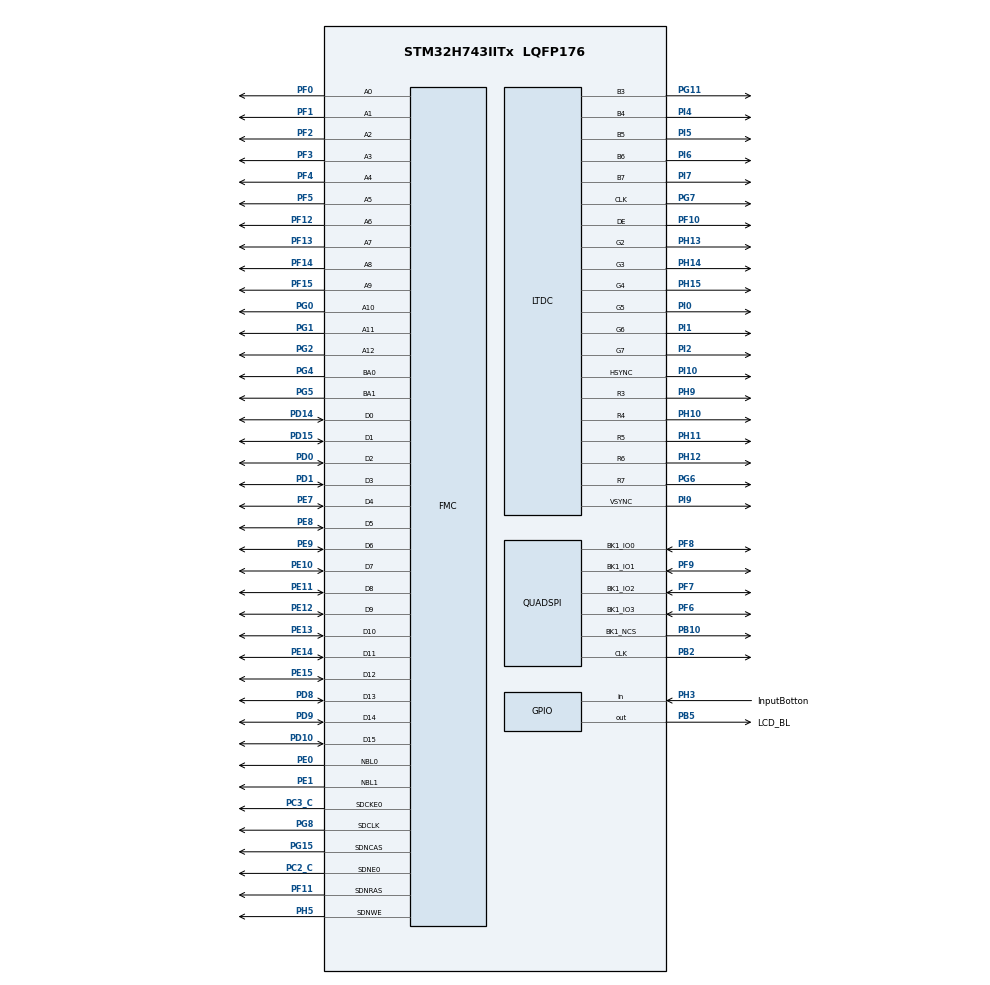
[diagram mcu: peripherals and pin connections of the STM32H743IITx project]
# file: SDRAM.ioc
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CORTEX_M7.CPU_DCache=Enabled
CORTEX_M7.CPU_ICache=Enabled
CORTEX_M7.MPU_Control=__NULL
CORTEX_M7.default_mode_Activation=1
DMA2D.AlphaModeForeground=DMA2D_REPLACE_ALPHA
DMA2D.ColorMode=DMA2D_OUTPUT_RGB565
DMA2D.InputAlphaForeground=255
DMA2D.Mode=DMA2D_M2M
FMC.CASLatency1=FMC_SDRAM_CAS_LATENCY_3
FMC.ColumnBitsNumber1=FMC_SDRAM_COLUMN_BITS_NUM_9
FMC.ExitSelfRefreshDelay1=7
FMC.LoadToActiveDelay1=2
FMC.RCDDelay1=2
FMC.RPDelay1=2
FMC.ReadPipeDelay1=FMC_SDRAM_RPIPE_DELAY_1
FMC.RowCycleDelay1=7
FMC.SDClockPeriod1=FMC_SDRAM_CLOCK_PERIOD_2
FMC.SelfRefreshTime1=4
FMC.WriteRecoveryTime1=3
FREERTOS.Tasks01=defaultTask,24,8910,StartDefaultTask,Default,NULL,Dynamic,NULL,NULL
FREERTOS.configTOTAL_HEAP_SIZE=100000
FREERTOS.configUSE_NEWLIB_REENTRANT=1
LTDC.ActiveH=272
LTDC.ActiveW=480
LTDC.Alpha_L0=255
LTDC.Blue=100
LTDC.FBStartAdress_L0=0xC0000000
LTDC.Green=100
LTDC.HBP=43
LTDC.HFP=8
LTDC.HSync=1
LTDC.ImageHeight_L0=272
LTDC.ImageWidth_L0=480
LTDC.Layers=0
LTDC.PixelFormat_L0=LTDC_PIXEL_FORMAT_RGB565
LTDC.Red=100
LTDC.VBP=12
LTDC.VFP=8
LTDC.VSync=1
LTDC.WindowX1_L0=480
LTDC.WindowY1_L0=272
Mcu.Family=STM32H7
Mcu.Name=STM32H743IITx
Mcu.Package=LQFP176
NVIC.DMA2D_IRQn=true\:5\:0\:false\:false\:true\:true\:true\:true\:true
NVIC.FMC_IRQn=true\:5\:0\:false\:false\:true\:true\:true\:true\:true
NVIC.LTDC_ER_IRQn=true\:5\:0\:false\:false\:true\:true\:true\:true\:true
NVIC.LTDC_IRQn=true\:5\:0\:false\:false\:true\:true\:true\:true\:true
NVIC.PriorityGroup=NVIC_PRIORITYGROUP_4
NVIC.TIM17_IRQn=true\:15\:0\:false\:false\:true\:false\:false\:true\:true
NVIC.TimeBase=TIM17_IRQn
NVIC.TimeBaseIP=TIM17
PB10.Mode=Single Bank 1
PB10.Signal=QUADSPI_BK1_NCS
PB2.Mode=Single Bank 1
PB2.Signal=QUADSPI_CLK
PB5.GPIO_Label=LCD_BL
PB5.Signal=GPIO_Output
PC2_C.GPIO_Mode=GPIO_MODE_AF_PP
PC2_C.GPIO_Speed_High_Default=GPIO_SPEED_FREQ_VERY_HIGH
PC2_C.Mode=SdramChipSelect1_1
PC2_C.Signal=FMC_SDNE0
PC3_C.GPIO_Mode=GPIO_MODE_AF_PP
PC3_C.GPIO_Speed_High_Default=GPIO_SPEED_FREQ_VERY_HIGH
PC3_C.Mode=SdramChipSelect1_1
PC3_C.Signal=FMC_SDCKE0
PD0.GPIO_Mode=GPIO_MODE_AF_PP
PD0.GPIO_Speed_High_Default=GPIO_SPEED_FREQ_VERY_HIGH
PD0.Signal=FMC_D2_DA2
PD1.GPIO_Mode=GPIO_MODE_AF_PP
PD1.GPIO_Speed_High_Default=GPIO_SPEED_FREQ_VERY_HIGH
PD1.Signal=FMC_D3_DA3
PD10.GPIO_Mode=GPIO_MODE_AF_PP
PD10.GPIO_Speed_High_Default=GPIO_SPEED_FREQ_VERY_HIGH
PD10.Signal=FMC_D15_DA15
PD14.GPIO_Mode=GPIO_MODE_AF_PP
PD14.GPIO_Speed_High_Default=GPIO_SPEED_FREQ_VERY_HIGH
PD14.Signal=FMC_D0_DA0
PD15.GPIO_Mode=GPIO_MODE_AF_PP
PD15.GPIO_Speed_High_Default=GPIO_SPEED_FREQ_VERY_HIGH
PD15.Signal=FMC_D1_DA1
PD8.GPIO_Mode=GPIO_MODE_AF_PP
PD8.GPIO_Speed_High_Default=GPIO_SPEED_FREQ_VERY_HIGH
PD8.Signal=FMC_D13_DA13
PD9.GPIO_Mode=GPIO_MODE_AF_PP
PD9.GPIO_Speed_High_Default=GPIO_SPEED_FREQ_VERY_HIGH
PD9.Signal=FMC_D14_DA14
PE0.GPIO_Mode=GPIO_MODE_AF_PP
PE0.GPIO_Speed_High_Default=GPIO_SPEED_FREQ_VERY_HIGH
PE0.Signal=FMC_NBL0
PE1.GPIO_Mode=GPIO_MODE_AF_PP
PE1.GPIO_Speed_High_Default=GPIO_SPEED_FREQ_VERY_HIGH
PE1.Signal=FMC_NBL1
PE10.GPIO_Mode=GPIO_MODE_AF_PP
PE10.GPIO_Speed_High_Default=GPIO_SPEED_FREQ_VERY_HIGH
PE10.Signal=FMC_D7_DA7
PE11.GPIO_Mode=GPIO_MODE_AF_PP
PE11.GPIO_Speed_High_Default=GPIO_SPEED_FREQ_VERY_HIGH
PE11.Signal=FMC_D8_DA8
PE12.GPIO_Mode=GPIO_MODE_AF_PP
PE12.GPIO_Speed_High_Default=GPIO_SPEED_FREQ_VERY_HIGH
PE12.Signal=FMC_D9_DA9
PE13.GPIO_Mode=GPIO_MODE_AF_PP
PE13.GPIO_Speed_High_Default=GPIO_SPEED_FREQ_VERY_HIGH
PE13.Signal=FMC_D10_DA10
PE14.GPIO_Mode=GPIO_MODE_AF_PP
PE14.GPIO_Speed_High_Default=GPIO_SPEED_FREQ_VERY_HIGH
PE14.Signal=FMC_D11_DA11
PE15.GPIO_Mode=GPIO_MODE_AF_PP
PE15.GPIO_Speed_High_Default=GPIO_SPEED_FREQ_VERY_HIGH
PE15.Signal=FMC_D12_DA12
PE7.GPIO_Mode=GPIO_MODE_AF_PP
PE7.GPIO_Speed_High_Default=GPIO_SPEED_FREQ_VERY_HIGH
PE7.Signal=FMC_D4_DA4
PE8.GPIO_Mode=GPIO_MODE_AF_PP
PE8.GPIO_Speed_High_Default=GPIO_SPEED_FREQ_VERY_HIGH
PE8.Signal=FMC_D5_DA5
PE9.GPIO_Mode=GPIO_MODE_AF_PP
PE9.GPIO_Speed_High_Default=GPIO_SPEED_FREQ_VERY_HIGH
PE9.Signal=FMC_D6_DA6
PF0.GPIO_Mode=GPIO_MODE_AF_PP
PF0.GPIO_Speed_High_Default=GPIO_SPEED_FREQ_VERY_HIGH
PF0.Signal=FMC_A0
PF1.GPIO_Mode=GPIO_MODE_AF_PP
PF1.GPIO_Speed_High_Default=GPIO_SPEED_FREQ_VERY_HIGH
PF1.Signal=FMC_A1
PF10.Mode=RGB565
PF10.Signal=LTDC_DE
PF11.GPIO_Mode=GPIO_MODE_AF_PP
PF11.GPIO_Speed_High_Default=GPIO_SPEED_FREQ_VERY_HIGH
PF11.Signal=FMC_SDNRAS
PF12.GPIO_Mode=GPIO_MODE_AF_PP
PF12.GPIO_Speed_High_Default=GPIO_SPEED_FREQ_VERY_HIGH
PF12.Signal=FMC_A6
PF13.GPIO_Mode=GPIO_MODE_AF_PP
PF13.GPIO_Speed_High_Default=GPIO_SPEED_FREQ_VERY_HIGH
PF13.Signal=FMC_A7
PF14.GPIO_Mode=GPIO_MODE_AF_PP
PF14.GPIO_Speed_High_Default=GPIO_SPEED_FREQ_VERY_HIGH
PF14.Signal=FMC_A8
PF15.GPIO_Mode=GPIO_MODE_AF_PP
PF15.GPIO_Speed_High_Default=GPIO_SPEED_FREQ_VERY_HIGH
PF15.Signal=FMC_A9
PF2.GPIO_Mode=GPIO_MODE_AF_PP
PF2.GPIO_Speed_High_Default=GPIO_SPEED_FREQ_VERY_HIGH
PF2.Signal=FMC_A2
PF3.GPIO_Mode=GPIO_MODE_AF_PP
PF3.GPIO_Speed_High_Default=GPIO_SPEED_FREQ_VERY_HIGH
PF3.Signal=FMC_A3
PF4.GPIO_Mode=GPIO_MODE_AF_PP
PF4.GPIO_Speed_High_Default=GPIO_SPEED_FREQ_VERY_HIGH
PF4.Signal=FMC_A4
PF5.GPIO_Mode=GPIO_MODE_AF_PP
PF5.GPIO_Speed_High_Default=GPIO_SPEED_FREQ_VERY_HIGH
PF5.Signal=FMC_A5
PF6.Mode=Single Bank 1
PF6.Signal=QUADSPI_BK1_IO3
PF7.Mode=Single Bank 1
PF7.Signal=QUADSPI_BK1_IO2
PF8.Mode=Single Bank 1
PF8.Signal=QUADSPI_BK1_IO0
PF9.Mode=Single Bank 1
PF9.Signal=QUADSPI_BK1_IO1
PG0.GPIO_Mode=GPIO_MODE_AF_PP
PG0.GPIO_Speed_High_Default=GPIO_SPEED_FREQ_VERY_HIGH
PG0.Signal=FMC_A10
PG1.GPIO_Mode=GPIO_MODE_AF_PP
PG1.GPIO_Speed_High_Default=GPIO_SPEED_FREQ_VERY_HIGH
PG1.Signal=FMC_A11
PG11.Mode=RGB565
PG11.Signal=LTDC_B3
PG15.GPIO_Mode=GPIO_MODE_AF_PP
PG15.GPIO_Speed_High_Default=GPIO_SPEED_FREQ_VERY_HIGH
PG15.Signal=FMC_SDNCAS
PG2.GPIO_Mode=GPIO_MODE_AF_PP
PG2.GPIO_Speed_High_Default=GPIO_SPEED_FREQ_VERY_HIGH
PG2.Signal=FMC_A12
PG4.GPIO_Mode=GPIO_MODE_AF_PP
PG4.GPIO_Speed_High_Default=GPIO_SPEED_FREQ_VERY_HIGH
PG4.Signal=FMC_A14_BA0
PG5.GPIO_Mode=GPIO_MODE_AF_PP
PG5.GPIO_Speed_High_Default=GPIO_SPEED_FREQ_VERY_HIGH
PG5.Signal=FMC_A15_BA1
PG6.Mode=RGB565
PG6.Signal=LTDC_R7
PG7.Mode=RGB565
PG7.Signal=LTDC_CLK
PG8.GPIO_Mode=GPIO_MODE_AF_PP
PG8.GPIO_Speed_High_Default=GPIO_SPEED_FREQ_VERY_HIGH
PG8.Signal=FMC_SDCLK
PH0-OSC_IN\ (PH0).Mode=HSE-External-Oscillator
PH0-OSC_IN\ (PH0).Signal=RCC_OSC_IN
PH1-OSC_OUT\ (PH1).Mode=HSE-External-Oscillator
PH1-OSC_OUT\ (PH1).Signal=RCC_OSC_OUT
PH10.Mode=RGB565
PH10.Signal=LTDC_R4
PH11.Mode=RGB565
PH11.Signal=LTDC_R5
PH12.Mode=RGB565
PH12.Signal=LTDC_R6
PH13.Mode=RGB565
PH13.Signal=LTDC_G2
PH14.Mode=RGB565
PH14.Signal=LTDC_G3
PH15.Mode=RGB565
PH15.Signal=LTDC_G4
PH3.GPIO_Label=InputBotton
PH3.Signal=GPIO_Input
PH5.Signal=FMC_SDNWE
PH9.Mode=RGB565
PH9.Signal=LTDC_R3
PI0.Mode=RGB565
PI0.Signal=LTDC_G5
PI1.Mode=RGB565
PI1.Signal=LTDC_G6
PI10.Mode=RGB565
PI10.Signal=LTDC_HSYNC
PI2.Mode=RGB565
PI2.Signal=LTDC_G7
PI4.Mode=RGB565
PI4.Signal=LTDC_B4
PI5.Mode=RGB565
PI5.Signal=LTDC_B5
PI6.Mode=RGB565
PI6.Signal=LTDC_B6
PI7.Mode=RGB565
PI7.Signal=LTDC_B7
PI9.Mode=RGB565
PI9.Signal=LTDC_VSYNC
ProjectManager.HeapSize=0x200
ProjectManager.StackSize=0x400
ProjectManager.TargetToolchain=STM32CubeIDE
RCC.ADCFreq_Value=50390625
RCC.APB1Freq_Value=120000000
RCC.APB2Freq_Value=120000000
RCC.APB3Freq_Value=120000000
RCC.APB4Freq_Value=120000000
RCC.CortexFreq_Value=480000000
RCC.D1PPRE=RCC_APB3_DIV2
RCC.D2PPRE1=RCC_APB1_DIV2
RCC.D2PPRE2=RCC_APB2_DIV2
RCC.D3PPRE=RCC_APB4_DIV2
RCC.DIVM1=5
RCC.DIVM3=25
RCC.DIVN1=192
RCC.DIVN3=200
RCC.DIVR3=10
RCC.FMCCLockSelection=RCC_FMCCLKSOURCE_CLKP
RCC.HCLKFreq_Value=240000000
RCC.HPRE=RCC_HCLK_DIV2
RCC.PLLFRACN=0
RCC.PLLSourceVirtual=RCC_PLLSOURCE_HSE
RCC.SYSCLKFreq_VALUE=480000000
RCC.SYSCLKSource=RCC_SYSCLKSOURCE_PLLCLK
RCC.USBFreq_Value=480000000
SH.FMC_A0.0=FMC_A0,13b-sda1
SH.FMC_A1.0=FMC_A1,13b-sda1
SH.FMC_A10.0=FMC_A10,13b-sda1
SH.FMC_A11.0=FMC_A11,13b-sda1
SH.FMC_A12.0=FMC_A12,13b-sda1
SH.FMC_A14_BA0.0=FMC_BA0,FourSdramBanks1
SH.FMC_A15_BA1.0=FMC_BA1,FourSdramBanks1
SH.FMC_A2.0=FMC_A2,13b-sda1
SH.FMC_A3.0=FMC_A3,13b-sda1
SH.FMC_A4.0=FMC_A4,13b-sda1
SH.FMC_A5.0=FMC_A5,13b-sda1
SH.FMC_A6.0=FMC_A6,13b-sda1
SH.FMC_A7.0=FMC_A7,13b-sda1
SH.FMC_A8.0=FMC_A8,13b-sda1
SH.FMC_A9.0=FMC_A9,13b-sda1
SH.FMC_D0_DA0.0=FMC_D0,sd-16b-d1
SH.FMC_D10_DA10.0=FMC_D10,sd-16b-d1
SH.FMC_D11_DA11.0=FMC_D11,sd-16b-d1
SH.FMC_D12_DA12.0=FMC_D12,sd-16b-d1
SH.FMC_D13_DA13.0=FMC_D13,sd-16b-d1
SH.FMC_D14_DA14.0=FMC_D14,sd-16b-d1
SH.FMC_D15_DA15.0=FMC_D15,sd-16b-d1
SH.FMC_D1_DA1.0=FMC_D1,sd-16b-d1
SH.FMC_D2_DA2.0=FMC_D2,sd-16b-d1
SH.FMC_D3_DA3.0=FMC_D3,sd-16b-d1
SH.FMC_D4_DA4.0=FMC_D4,sd-16b-d1
SH.FMC_D5_DA5.0=FMC_D5,sd-16b-d1
SH.FMC_D6_DA6.0=FMC_D6,sd-16b-d1
SH.FMC_D7_DA7.0=FMC_D7,sd-16b-d1
SH.FMC_D8_DA8.0=FMC_D8,sd-16b-d1
SH.FMC_D9_DA9.0=FMC_D9,sd-16b-d1
SH.FMC_NBL0.0=FMC_NBL0,Sd2ByteEnable1
SH.FMC_NBL1.0=FMC_NBL1,Sd2ByteEnable1
SH.FMC_SDCLK.0=FMC_SDCLK,13b-sda1
SH.FMC_SDNCAS.0=FMC_SDNCAS,13b-sda1
SH.FMC_SDNRAS.0=FMC_SDNRAS,13b-sda1
SH.FMC_SDNWE.0=FMC_SDNWE,13b-sda1
STMicroelectronics.X-CUBE-TOUCHGFX.4.26.0.ApplicationCcGraphicsJjApplication=TouchGFXOoGenerator
STMicroelectronics.X-CUBE-TOUCHGFX.4.26.0.tgfx_address1=0xC0000000
STMicroelectronics.X-CUBE-TOUCHGFX.4.26.0.tgfx_address2=0xC4000000
STMicroelectronics.X-CUBE-TOUCHGFX.4.26.0.tgfx_buffering_strategy=Single
STMicroelectronics.X-CUBE-TOUCHGFX.4.26.0.tgfx_display_interface=disp_ltdc
STMicroelectronics.X-CUBE-TOUCHGFX.4.26.0.tgfx_framebuffer_stride=Enabled
STMicroelectronics.X-CUBE-TOUCHGFX.4.26.0.tgfx_hardware_accelerator=dma_2d
STMicroelectronics.X-CUBE-TOUCHGFX.4.26.0.tgfx_location=By Address
STMicroelectronics.X-CUBE-TOUCHGFX.4.26.0.tgfx_oswrapper=CMSIS V2
STMicroelectronics.X-CUBE-TOUCHGFX.4.26.0.tgfx_vsync=vsync_ltdc
STMicroelectronics.X-CUBE-TOUCHGFX.4.26.0_IsPackSelfContextualization=true
VP_CRC_VS_CRC.Mode=CRC_Activate
VP_DMA2D_VS_DMA2D.Mode=DMA2D_Activate
VP_FREERTOS_VS_CMSIS_V2.Mode=CMSIS_V2
VP_MEMORYMAP_VS_MEMORYMAP.Mode=CurAppReg
VP_STMicroelectronics.X-CUBE-TOUCHGFX_VS_GraphicsJjApplication_4.26.0.Mode=GraphicsJjApplication
VP_SYS_VS_tim17.Mode=TIM17
board=custom

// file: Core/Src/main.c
/* USER CODE BEGIN Header */
/**
  ******************************************************************************
  * @file           : main.c
  * @brief          : Main program body
  ******************************************************************************
  * @attention
  *
  * Copyright (c) 2025 STMicroelectronics.
  * All rights reserved.
  *
  * This software is licensed under terms that can be found in the LICENSE file
  * in the root directory of this software component.
  * If no LICENSE file comes with this software, it is provided AS-IS.
  *
  ******************************************************************************
  */
/* USER CODE END Header */
#include "main.h"
#include "cmsis_os.h"
#include "app_touchgfx.h"

/* USER CODE BEGIN Includes */
#include "imag.h"
/* USER CODE END Includes */

/* USER CODE BEGIN PTD */
#define SDRAM_BANK_ADDR ((uint32_t)0xC0000000) // Bank 1 base address
#define TEST_SIZE 256 // Test 256 16-bit words (512 bytes)
/* USER CODE END PTD */

/* USER CODE BEGIN PD */
#define SDRAM_Size 32*1024*1024 //32M bytes
#define SDRAM_BANK_ADDR ((uint32_t)0xC0000000) // FMC SDRAM data base address
#define FMC_COMMAND_TARGET_BANK FMC_SDRAM_CMD_TARGET_BANK1 // SDRAM bank selection
#define SDRAM_TIMEOUT ((uint32_t)0x1000) // Timeout judgment time

#define SDRAM_MODEREG_BURST_LENGTH_1             ((uint16_t)0x0000)
#define SDRAM_MODEREG_BURST_LENGTH_2             ((uint16_t)0x0001)
#define SDRAM_MODEREG_BURST_LENGTH_4             ((uint16_t)0x0002)
#define SDRAM_MODEREG_BURST_LENGTH_8             ((uint16_t)0x0004)
#define SDRAM_MODEREG_BURST_TYPE_SEQUENTIAL      ((uint16_t)0x0000)
#define SDRAM_MODEREG_BURST_TYPE_INTERLEAVED     ((uint16_t)0x0008)
#define SDRAM_MODEREG_CAS_LATENCY_2              ((uint16_t)0x0020)
#define SDRAM_MODEREG_CAS_LATENCY_3              ((uint16_t)0x0030)
#define SDRAM_MODEREG_OPERATING_MODE_STANDARD    ((uint16_t)0x0000)
#define SDRAM_MODEREG_WRITEBURST_MODE_PROGRAMMED ((uint16_t)0x0000)
#define SDRAM_MODEREG_WRITEBURST_MODE_SINGLE     ((uint16_t)0x0200)

FMC_SDRAM_CommandTypeDef command; //Control command

/* USER CODE END PD */

/* USER CODE BEGIN PM */
#define LCD_WIDTH  480
#define LCD_HEIGHT 272
#define FRAMEBUFFER_ADDR 0xC0000000 // SDRAM base address

#define COLOR_RED   0xF800
#define COLOR_GREEN 0x07E0
#define COLOR_BLUE  0x001F
#define COLOR_BLACK 0x0000
#define COLOR_WHITE 0xFFFF
/* USER CODE END PM */

CRC_HandleTypeDef hcrc;

DMA2D_HandleTypeDef hdma2d;

LTDC_HandleTypeDef hltdc;

QSPI_HandleTypeDef hqspi;

SDRAM_HandleTypeDef hsdram1;

/* Definitions for defaultTask */
osThreadId_t defaultTaskHandle;
const osThreadAttr_t defaultTask_attributes = {
  .name = "defaultTask",
  .stack_size = 8910 * 4,
  .priority = (osPriority_t) osPriorityNormal,
};

void SystemClock_Config(void);
void PeriphCommonClock_Config(void);
static void MX_GPIO_Init(void);
static void MX_FMC_Init(void);
static void MX_LTDC_Init(void);
static void MX_DMA2D_Init(void);
static void MX_CRC_Init(void);
static void MX_QUADSPI_Init(void);
void StartDefaultTask(void *argument);

/* USER CODE BEGIN PFP */
void MPU_Config(void);
void FillFramebuffer(uint32_t framebuffer_addr, uint16_t color, uint16_t width, uint16_t height);

uint16_t *fb_ptr = (uint16_t *)FRAMEBUFFER_ADDR;
/* USER CODE END PFP */

/* USER CODE BEGIN 0 */
uint32_t GeneralCounter =0 ;

void SDRAM_Initialization_Sequence(SDRAM_HandleTypeDef *hsdram, FMC_SDRAM_CommandTypeDef *Command)
{
	__IO uint32_t tmpmrd = 0;

	/* Configure a clock configuration enable command */
	Command->CommandMode = FMC_SDRAM_CMD_CLK_ENABLE; // Turn on the SDRAM clock
	Command->CommandTarget = FMC_COMMAND_TARGET_BANK; //Select the area to be controlled
	Command->AutoRefreshNumber 		= 1;
	Command->ModeRegisterDefinition 	= 0;

	HAL_SDRAM_SendCommand(hsdram, Command, SDRAM_TIMEOUT); // Send control command
	HAL_Delay(1); // Delay wait

	/* Configure a PALL (precharge all) command */
	Command->CommandMode = FMC_SDRAM_CMD_PALL; // Precharge command
	Command->CommandTarget = FMC_COMMAND_TARGET_BANK; //Select the area to be controlled
	Command->AutoRefreshNumber 		= 1;
	Command->ModeRegisterDefinition 	= 0;

	HAL_SDRAM_SendCommand(hsdram, Command, SDRAM_TIMEOUT); // Send control command

	/* Configure a Auto-Refresh command */
	Command->CommandMode = FMC_SDRAM_CMD_AUTOREFRESH_MODE; // Use automatic refresh
	Command->CommandTarget = FMC_COMMAND_TARGET_BANK; //Select the area to be controlled
	Command->AutoRefreshNumber = 8; //Number of automatic refreshes
	Command->ModeRegisterDefinition 	= 0;

	HAL_SDRAM_SendCommand(hsdram, Command, SDRAM_TIMEOUT); // Send control command

	/* Program the external memory mode register */
	tmpmrd = (uint32_t)SDRAM_MODEREG_BURST_LENGTH_2         |
							SDRAM_MODEREG_BURST_TYPE_SEQUENTIAL   |
							SDRAM_MODEREG_CAS_LATENCY_3           |
							SDRAM_MODEREG_OPERATING_MODE_STANDARD |
							SDRAM_MODEREG_WRITEBURST_MODE_SINGLE;

	Command->CommandMode = FMC_SDRAM_CMD_LOAD_MODE; // Load mode register command
	Command->CommandTarget = FMC_COMMAND_TARGET_BANK; //Select the area to be controlled
	Command->AutoRefreshNumber 		= 1;
	Command->ModeRegisterDefinition 	= tmpmrd;

	HAL_SDRAM_SendCommand(hsdram, Command, SDRAM_TIMEOUT); // Send control command

	HAL_SDRAM_ProgramRefreshRate(hsdram, 918); // Configure refresh rate

}

uint16_t  *DataTOLCD = (uint16_t*)FRAMEBUFFER_ADDR ;
/* USER CODE END 0 */

int main(void)
{

  /* USER CODE BEGIN 1 */
  MPU_Config();
  /* USER CODE END 1 */

  /* Enable the CPU Cache */

  /* Enable I-Cache---------------------------------------------------------*/
  SCB_EnableICache();

  /* Enable D-Cache---------------------------------------------------------*/
  SCB_EnableDCache();

  /* MCU Configuration--------------------------------------------------------*/

  /* Reset of all peripherals, Initializes the Flash interface and the Systick. */
  HAL_Init();

  /* Configure the system clock */
  SystemClock_Config();

  /* Configure the peripherals common clocks */
  PeriphCommonClock_Config();

  /* USER CODE BEGIN SysInit */
//  MPU_Config();
  /* USER CODE END SysInit */

  /* Initialize all configured peripherals */
  MX_GPIO_Init();
  MX_FMC_Init();
  MX_LTDC_Init();
  MX_DMA2D_Init();
  MX_CRC_Init();
  MX_QUADSPI_Init();
  MX_TouchGFX_Init();
  /* Call PreOsInit function */
  MX_TouchGFX_PreOSInit();
  /* USER CODE BEGIN 2 */
  HAL_GPIO_WritePin(LCD_BL_GPIO_Port, LCD_BL_Pin, 1);

//	uint16_t write_pattern = 0xA5A5; // Test patterns
//	uint16_t read_data;
//	uint32_t i;
//	uint8_t errors = 0;

//      // Write pattern to SDRAM
//      for (i = 0; i < TEST_SIZE; i++) {
//          *(__IO uint32_t*)(SDRAM_BANK_ADDR + 4*i) = (uint32_t)0x00;
//      }
//
//      for (i = 0; i < TEST_SIZE; i++) {
//          *(__IO uint32_t*)(SDRAM_BANK_ADDR + 4*i) = (uint32_t)0x19;
//      }
//
//      // Read back and verify
//      for (i = 0; i < TEST_SIZE; i++) {
//          read_data = *(__IO uint16_t*)(SDRAM_BANK_ADDR + (i * 2));
//          if (read_data != write_pattern) {
//              errors++; // Track errors
//          }
//      }

      LTDC_LayerCfgTypeDef layer_cfg = {0};
      layer_cfg.WindowX0 = 0;
      layer_cfg.WindowX1 = LCD_WIDTH;
      layer_cfg.WindowY0 = 0;
      layer_cfg.WindowY1 = LCD_HEIGHT;
      layer_cfg.PixelFormat = LTDC_PIXEL_FORMAT_RGB565;
      layer_cfg.FBStartAdress = FRAMEBUFFER_ADDR; // SDRAM base
      layer_cfg.Alpha = 255; // Opaque
      layer_cfg.Alpha0 = 0;
      layer_cfg.BlendingFactor1 = LTDC_BLENDING_FACTOR1_PAxCA;
      layer_cfg.BlendingFactor2 = LTDC_BLENDING_FACTOR2_PAxCA;
      layer_cfg.ImageWidth = LCD_WIDTH;
      layer_cfg.ImageHeight = LCD_HEIGHT;

      HAL_LTDC_ConfigLayer(&hltdc, &layer_cfg, 0); // Layer 0
      HAL_LTDC_EnableColorKeying(&hltdc, 0); // Optional, disable color keying
      HAL_LTDC_SetAddress(&hltdc, FRAMEBUFFER_ADDR, 0); // Set framebuffer address
  /* USER CODE END 2 */

  /* Init scheduler */
  osKernelInitialize();

  /* Create the thread(s) */
  /* creation of defaultTask */
  defaultTaskHandle = osThreadNew(StartDefaultTask, NULL, &defaultTask_attributes);

  /* Start scheduler */
  osKernelStart();

  /* We should never get here as control is now taken by the scheduler */

  /* Infinite loop */
  /* USER CODE BEGIN WHILE */
  while (1)
  {
//
//		FillFramebuffer(FRAMEBUFFER_ADDR, COLOR_RED, LCD_WIDTH, LCD_HEIGHT);
//		HAL_Delay(500); // Wait 2 seconds
//
//		// Fill with green
//		FillFramebuffer(FRAMEBUFFER_ADDR, COLOR_GREEN, LCD_WIDTH, LCD_HEIGHT);
//		HAL_Delay(500);
//
//		// Fill with blue
//		FillFramebuffer(FRAMEBUFFER_ADDR, COLOR_BLUE, LCD_WIDTH, LCD_HEIGHT);
//		HAL_Delay(500);
//
//		// Fill with white
//		FillFramebuffer(FRAMEBUFFER_ADDR, COLOR_WHITE, LCD_WIDTH, LCD_HEIGHT);
//		HAL_Delay(500);
//
//		// Fill with black
//		FillFramebuffer(FRAMEBUFFER_ADDR, COLOR_BLACK, LCD_WIDTH, LCD_HEIGHT);
//		HAL_Delay(500);
//
//	    for(int i =0 ;i  < sizeof(gImage_TestImage) / 2  ;i++){
//	    	fb_ptr[i] = gImage_TestImage[i] | gImage_TestImage[i+1];
//	    }

//     for(int i =0  ; i< sizeof(IMG_20250926_153935 ) ;i++){
//    	 DataTOLCD[i] = IMG_20250926_153935[i];
//    	 i++;
//     }
//	  HAL_DMA2D_Start(&hdma2d, (uint32_t)IMG_20250926_153935, FRAMEBUFFER_ADDR, 480, 272);
//	  HAL_DMA2D_PollForTransfer(&hdma2d, 100);
//
//	  HAL_Delay(500);
//
//	  HAL_DMA2D_Start(&hdma2d, (uint32_t)AliImage1, FRAMEBUFFER_ADDR, 480, 272);
//	  HAL_DMA2D_PollForTransfer(&hdma2d, 100);
//	  HAL_Delay(500);

	  HAL_DMA2D_Start(&hdma2d, (uint32_t)AlireImage2, FRAMEBUFFER_ADDR, 480, 272);
	  HAL_DMA2D_PollForTransfer(&hdma2d, 100);

	  HAL_Delay(500);
//     HAL_Delay(500) ;
//
//
//     for(int i =0  ; i< 272 * 480 ;i++){
//    	 DataTOLCD[i] = COLOR_GREEN;
//     }
//
//     HAL_Delay(500) ;

	  GeneralCounter ++ ;
    /* USER CODE END WHILE */

  }
}

void SystemClock_Config(void)
{
  RCC_OscInitTypeDef RCC_OscInitStruct = {0};
  RCC_ClkInitTypeDef RCC_ClkInitStruct = {0};

  /** Supply configuration update enable
  */
  HAL_PWREx_ConfigSupply(PWR_LDO_SUPPLY);

  /** Configure the main internal regulator output voltage
  */
  __HAL_PWR_VOLTAGESCALING_CONFIG(PWR_REGULATOR_VOLTAGE_SCALE0);

  while(!__HAL_PWR_GET_FLAG(PWR_FLAG_VOSRDY)) {}

  /** Initializes the RCC Oscillators according to the specified parameters
  * in the RCC_OscInitTypeDef structure.
  */
  RCC_OscInitStruct.OscillatorType = RCC_OSCILLATORTYPE_HSI|RCC_OSCILLATORTYPE_HSE;
  RCC_OscInitStruct.HSEState = RCC_HSE_ON;
  RCC_OscInitStruct.HSIState = RCC_HSI_DIV1;
  RCC_OscInitStruct.HSICalibrationValue = RCC_HSICALIBRATION_DEFAULT;
  RCC_OscInitStruct.PLL.PLLState = RCC_PLL_ON;
  RCC_OscInitStruct.PLL.PLLSource = RCC_PLLSOURCE_HSE;
  RCC_OscInitStruct.PLL.PLLM = 5;
  RCC_OscInitStruct.PLL.PLLN = 192;
  RCC_OscInitStruct.PLL.PLLP = 2;
  RCC_OscInitStruct.PLL.PLLQ = 2;
  RCC_OscInitStruct.PLL.PLLR = 2;
  RCC_OscInitStruct.PLL.PLLRGE = RCC_PLL1VCIRANGE_2;
  RCC_OscInitStruct.PLL.PLLVCOSEL = RCC_PLL1VCOWIDE;
  RCC_OscInitStruct.PLL.PLLFRACN = 0;
  if (HAL_RCC_OscConfig(&RCC_OscInitStruct) != HAL_OK)
  {
    Error_Handler();
  }

  /** Initializes the CPU, AHB and APB buses clocks
  */
  RCC_ClkInitStruct.ClockType = RCC_CLOCKTYPE_HCLK|RCC_CLOCKTYPE_SYSCLK
                              |RCC_CLOCKTYPE_PCLK1|RCC_CLOCKTYPE_PCLK2
                              |RCC_CLOCKTYPE_D3PCLK1|RCC_CLOCKTYPE_D1PCLK1;
  RCC_ClkInitStruct.SYSCLKSource = RCC_SYSCLKSOURCE_PLLCLK;
  RCC_ClkInitStruct.SYSCLKDivider = RCC_SYSCLK_DIV1;
  RCC_ClkInitStruct.AHBCLKDivider = RCC_HCLK_DIV2;
  RCC_ClkInitStruct.APB3CLKDivider = RCC_APB3_DIV2;
  RCC_ClkInitStruct.APB1CLKDivider = RCC_APB1_DIV2;
  RCC_ClkInitStruct.APB2CLKDivider = RCC_APB2_DIV2;
  RCC_ClkInitStruct.APB4CLKDivider = RCC_APB4_DIV2;

  if (HAL_RCC_ClockConfig(&RCC_ClkInitStruct, FLASH_LATENCY_4) != HAL_OK)
  {
    Error_Handler();
  }
}

void PeriphCommonClock_Config(void)
{
  RCC_PeriphCLKInitTypeDef PeriphClkInitStruct = {0};

  /** Initializes the peripherals clock
  */
  PeriphClkInitStruct.PeriphClockSelection = RCC_PERIPHCLK_CKPER;
  PeriphClkInitStruct.CkperClockSelection = RCC_CLKPSOURCE_HSI;
  if (HAL_RCCEx_PeriphCLKConfig(&PeriphClkInitStruct) != HAL_OK)
  {
    Error_Handler();
  }
}

static void MX_CRC_Init(void)
{

  hcrc.Instance = CRC;
  hcrc.Init.DefaultPolynomialUse = DEFAULT_POLYNOMIAL_ENABLE;
  hcrc.Init.DefaultInitValueUse = DEFAULT_INIT_VALUE_ENABLE;
  hcrc.Init.InputDataInversionMode = CRC_INPUTDATA_INVERSION_NONE;
  hcrc.Init.OutputDataInversionMode = CRC_OUTPUTDATA_INVERSION_DISABLE;
  hcrc.InputDataFormat = CRC_INPUTDATA_FORMAT_BYTES;
  if (HAL_CRC_Init(&hcrc) != HAL_OK)
  {
    Error_Handler();
  }

}

static void MX_DMA2D_Init(void)
{

  hdma2d.Instance = DMA2D;
  hdma2d.Init.Mode = DMA2D_M2M;
  hdma2d.Init.ColorMode = DMA2D_OUTPUT_RGB565;
  hdma2d.Init.OutputOffset = 0;
  hdma2d.LayerCfg[1].InputOffset = 0;
  hdma2d.LayerCfg[1].InputColorMode = DMA2D_INPUT_RGB565;
  hdma2d.LayerCfg[1].AlphaMode = DMA2D_REPLACE_ALPHA;
  hdma2d.LayerCfg[1].InputAlpha = 255;
  hdma2d.LayerCfg[1].AlphaInverted = DMA2D_REGULAR_ALPHA;
  hdma2d.LayerCfg[1].RedBlueSwap = DMA2D_RB_REGULAR;
  hdma2d.LayerCfg[1].ChromaSubSampling = DMA2D_NO_CSS;
  if (HAL_DMA2D_Init(&hdma2d) != HAL_OK)
  {
    Error_Handler();
  }
  if (HAL_DMA2D_ConfigLayer(&hdma2d, 1) != HAL_OK)
  {
    Error_Handler();
  }

}

static void MX_LTDC_Init(void)
{

  LTDC_LayerCfgTypeDef pLayerCfg = {0};

  hltdc.Instance = LTDC;
  hltdc.Init.HSPolarity = LTDC_HSPOLARITY_AL;
  hltdc.Init.VSPolarity = LTDC_VSPOLARITY_AL;
  hltdc.Init.DEPolarity = LTDC_DEPOLARITY_AL;
  hltdc.Init.PCPolarity = LTDC_PCPOLARITY_IPC;
  hltdc.Init.HorizontalSync = 0;
  hltdc.Init.VerticalSync = 0;
  hltdc.Init.AccumulatedHBP = 43;
  hltdc.Init.AccumulatedVBP = 12;
  hltdc.Init.AccumulatedActiveW = 523;
  hltdc.Init.AccumulatedActiveH = 284;
  hltdc.Init.TotalWidth = 531;
  hltdc.Init.TotalHeigh = 292;
  hltdc.Init.Backcolor.Blue = 100;
  hltdc.Init.Backcolor.Green = 100;
  hltdc.Init.Backcolor.Red = 100;
  if (HAL_LTDC_Init(&hltdc) != HAL_OK)
  {
    Error_Handler();
  }
  pLayerCfg.WindowX0 = 0;
  pLayerCfg.WindowX1 = 480;
  pLayerCfg.WindowY0 = 0;
  pLayerCfg.WindowY1 = 272;
  pLayerCfg.PixelFormat = LTDC_PIXEL_FORMAT_RGB565;
  pLayerCfg.Alpha = 255;
  pLayerCfg.Alpha0 = 0;
  pLayerCfg.BlendingFactor1 = LTDC_BLENDING_FACTOR1_CA;
  pLayerCfg.BlendingFactor2 = LTDC_BLENDING_FACTOR2_CA;
  pLayerCfg.FBStartAdress = 0xC0000000;
  pLayerCfg.ImageWidth = 480;
  pLayerCfg.ImageHeight = 272;
  pLayerCfg.Backcolor.Blue = 0;
  pLayerCfg.Backcolor.Green = 0;
  pLayerCfg.Backcolor.Red = 0;
  if (HAL_LTDC_ConfigLayer(&hltdc, &pLayerCfg, 0) != HAL_OK)
  {
    Error_Handler();
  }

}

static void MX_QUADSPI_Init(void)
{

  /* QUADSPI parameter configuration*/
  hqspi.Instance = QUADSPI;
  hqspi.Init.ClockPrescaler = 255;
  hqspi.Init.FifoThreshold = 1;
  hqspi.Init.SampleShifting = QSPI_SAMPLE_SHIFTING_NONE;
  hqspi.Init.FlashSize = 1;
  hqspi.Init.ChipSelectHighTime = QSPI_CS_HIGH_TIME_1_CYCLE;
  hqspi.Init.ClockMode = QSPI_CLOCK_MODE_0;
  hqspi.Init.FlashID = QSPI_FLASH_ID_1;
  hqspi.Init.DualFlash = QSPI_DUALFLASH_DISABLE;
  if (HAL_QSPI_Init(&hqspi) != HAL_OK)
  {
    Error_Handler();
  }

}

/* FMC initialization function */
static void MX_FMC_Init(void)
{

  FMC_SDRAM_TimingTypeDef SdramTiming = {0};

  /** Perform the SDRAM1 memory initialization sequence
  */
  hsdram1.Instance = FMC_SDRAM_DEVICE;
  /* hsdram1.Init */
  hsdram1.Init.SDBank = FMC_SDRAM_BANK1;
  hsdram1.Init.ColumnBitsNumber = FMC_SDRAM_COLUMN_BITS_NUM_9;
  hsdram1.Init.RowBitsNumber = FMC_SDRAM_ROW_BITS_NUM_13;
  hsdram1.Init.MemoryDataWidth = FMC_SDRAM_MEM_BUS_WIDTH_16;
  hsdram1.Init.InternalBankNumber = FMC_SDRAM_INTERN_BANKS_NUM_4;
  hsdram1.Init.CASLatency = FMC_SDRAM_CAS_LATENCY_3;
  hsdram1.Init.WriteProtection = FMC_SDRAM_WRITE_PROTECTION_DISABLE;
  hsdram1.Init.SDClockPeriod = FMC_SDRAM_CLOCK_PERIOD_2;
  hsdram1.Init.ReadBurst = FMC_SDRAM_RBURST_DISABLE;
  hsdram1.Init.ReadPipeDelay = FMC_SDRAM_RPIPE_DELAY_1;
  /* SdramTiming */
  SdramTiming.LoadToActiveDelay = 2;
  SdramTiming.ExitSelfRefreshDelay = 7;
  SdramTiming.SelfRefreshTime = 4;
  SdramTiming.RowCycleDelay = 7;
  SdramTiming.WriteRecoveryTime = 3;
  SdramTiming.RPDelay = 2;
  SdramTiming.RCDDelay = 2;

  if (HAL_SDRAM_Init(&hsdram1, &SdramTiming) != HAL_OK)
  {
    Error_Handler( );
  }

  /* USER CODE BEGIN FMC_Init 2 */
//	FMC_SDRAM_TimingTypeDef SdramTiming = {0};

	hsdram1.Instance = FMC_SDRAM_DEVICE;
	/* hsdram1.Init */
	hsdram1.Init.SDBank = FMC_SDRAM_BANK1; //Select BANK area
	hsdram1.Init.ColumnBitsNumber = FMC_SDRAM_COLUMN_BITS_NUM_9; // Row address width
	hsdram1.Init.RowBitsNumber = FMC_SDRAM_ROW_BITS_NUM_13; // Column address line width
	hsdram1.Init.MemoryDataWidth = FMC_SDRAM_MEM_BUS_WIDTH_16; // Data width
	hsdram1.Init.InternalBankNumber 		= FMC_SDRAM_INTERN_BANKS_NUM_4;        // bankÊýÁ¿
	hsdram1.Init.CASLatency 				= FMC_SDRAM_CAS_LATENCY_3;             //	CAS
	hsdram1.Init.WriteProtection = FMC_SDRAM_WRITE_PROTECTION_DISABLE; // Disable write protection
	hsdram1.Init.SDClockPeriod = FMC_SDRAM_CLOCK_PERIOD_2; // Frequency division
	hsdram1.Init.ReadBurst = FMC_SDRAM_RBURST_ENABLE; // Burst mode
	hsdram1.Init.ReadPipeDelay = FMC_SDRAM_RPIPE_DELAY_1; // Read delay

	/* SdramTiming */
	SdramTiming.LoadToActiveDelay 		= 2;
	SdramTiming.ExitSelfRefreshDelay = 7;
	SdramTiming.SelfRefreshTime = 4;
	SdramTiming.RowCycleDelay 				= 7;
	SdramTiming.WriteRecoveryTime 		= 2;
	SdramTiming.RPDelay 						= 2;
	SdramTiming.RCDDelay 					= 2;

	HAL_SDRAM_Init(&hsdram1, &SdramTiming); // Initialize the FMC interface

	SDRAM_Initialization_Sequence(&hsdram1,&command);//ÅäÖÃSDRAM
  /* USER CODE END FMC_Init 2 */
}

static void MX_GPIO_Init(void)
{
  GPIO_InitTypeDef GPIO_InitStruct = {0};

  /* GPIO Ports Clock Enable */
  __HAL_RCC_GPIOI_CLK_ENABLE();
  __HAL_RCC_GPIOF_CLK_ENABLE();
  __HAL_RCC_GPIOH_CLK_ENABLE();
  __HAL_RCC_GPIOC_CLK_ENABLE();
  __HAL_RCC_GPIOB_CLK_ENABLE();
  __HAL_RCC_GPIOG_CLK_ENABLE();
  __HAL_RCC_GPIOE_CLK_ENABLE();
  __HAL_RCC_GPIOD_CLK_ENABLE();

  /*Configure GPIO pin Output Level */
  HAL_GPIO_WritePin(LCD_BL_GPIO_Port, LCD_BL_Pin, GPIO_PIN_RESET);

  /*Configure GPIO pin : InputBotton_Pin */
  GPIO_InitStruct.Pin = InputBotton_Pin;
  GPIO_InitStruct.Mode = GPIO_MODE_INPUT;
  GPIO_InitStruct.Pull = GPIO_NOPULL;
  HAL_GPIO_Init(InputBotton_GPIO_Port, &GPIO_InitStruct);

  /*Configure GPIO pin : LCD_BL_Pin */
  GPIO_InitStruct.Pin = LCD_BL_Pin;
  GPIO_InitStruct.Mode = GPIO_MODE_OUTPUT_PP;
  GPIO_InitStruct.Pull = GPIO_NOPULL;
  GPIO_InitStruct.Speed = GPIO_SPEED_FREQ_LOW;
  HAL_GPIO_Init(LCD_BL_GPIO_Port, &GPIO_InitStruct);

}

/* USER CODE BEGIN 4 */
void MPU_Config(void)
{
	MPU_Region_InitTypeDef MPU_InitStruct;

	HAL_MPU_Disable(); // Disable first MPU

	MPU_InitStruct.Enable           = MPU_REGION_ENABLE;
	MPU_InitStruct.BaseAddress      = SDRAM_BANK_ADDR;
	MPU_InitStruct.Size             = MPU_REGION_SIZE_32MB;
	MPU_InitStruct.AccessPermission = MPU_REGION_FULL_ACCESS;
	MPU_InitStruct.IsBufferable     = MPU_ACCESS_NOT_BUFFERABLE;
	MPU_InitStruct.IsCacheable      = MPU_ACCESS_CACHEABLE;
	MPU_InitStruct.IsShareable      = MPU_ACCESS_NOT_SHAREABLE;
	MPU_InitStruct.Number           = MPU_REGION_NUMBER2;
	MPU_InitStruct.TypeExtField     = MPU_TEX_LEVEL0;
	MPU_InitStruct.SubRegionDisable = 0x00;
	MPU_InitStruct.DisableExec      = MPU_INSTRUCTION_ACCESS_ENABLE;

	HAL_MPU_ConfigRegion(&MPU_InitStruct);

	HAL_MPU_Enable(MPU_PRIVILEGED_DEFAULT); // Enable MPU
}

void FillFramebuffer(uint32_t framebuffer_addr, uint16_t color, uint16_t width, uint16_t height) {
    uint32_t num_pixels = width * height;

    for (uint32_t i = 0; i < num_pixels; i++) {
        fb_ptr[i] = color;
    }
}
/* USER CODE END 4 */

void StartDefaultTask(void *argument)
{
  /* USER CODE BEGIN 5 */
  MX_TouchGFX_Process();

  /* Infinite loop */
  for(;;)
  {

    osDelay(10);
  }
  /* USER CODE END 5 */
}

void HAL_TIM_PeriodElapsedCallback(TIM_HandleTypeDef *htim)
{
  if (htim->Instance == TIM17)
  {
    HAL_IncTick();
  }
}

void Error_Handler(void)
{
  __disable_irq();
  while (1)
  {
  }
}
